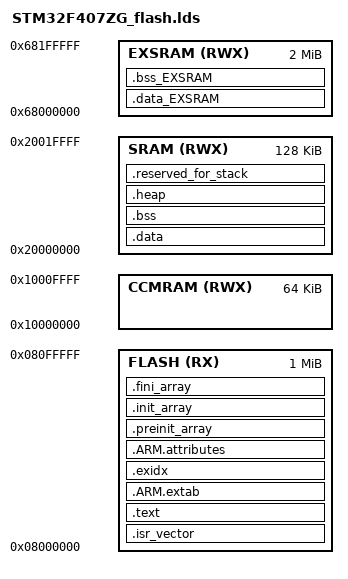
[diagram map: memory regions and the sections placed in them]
/* Generated by LinkerScriptGenerator [http://visualgdb.com/tools/LinkerScriptGenerator]
 * Target: STM32F407ZG
 * The file is provided under the BSD license.
 */

ENTRY(Reset_Handler)

MEMORY
{
	FLASH (RX)   : ORIGIN = 0x08000000, LENGTH = 1M
	SRAM (RWX)   : ORIGIN = 0x20000000, LENGTH = 128K
	CCMRAM (RWX) : ORIGIN = 0x10000000, LENGTH = 64K
  EXSRAM (RWX)   : ORIGIN = 0x68000000, LENGTH = 2M
}

_estack = 0x20020000;

SECTIONS
{
	.isr_vector :
	{
		. = ALIGN(4);
		KEEP(*(.isr_vector))
		. = ALIGN(4);
	} > FLASH

	.text :
	{
		. = ALIGN(4);
		_stext = .;

		*(.text)
		*(.text*)
		*(.rodata)
		*(.rodata*)
		*(.glue_7)
		*(.glue_7t)
		KEEP(*(.init))
		KEEP(*(.fini))
		. = ALIGN(4);
		_etext = .;

	} > FLASH

	.ARM.extab :
	{
		. = ALIGN(4);
		*(.ARM.extab)
		*(.gnu.linkonce.armextab.*)
		. = ALIGN(4);
	} > FLASH

	.exidx :
	{
		. = ALIGN(4);
		PROVIDE(__exidx_start = .);
		*(.ARM.exidx*)
		. = ALIGN(4);
		PROVIDE(__exidx_end = .);
	} > FLASH

	.ARM.attributes :
	{
		*(.ARM.attributes)
	} > FLASH

	.preinit_array :
	{
		PROVIDE(__preinit_array_start = .);
		KEEP(*(.preinit_array*))
		PROVIDE(__preinit_array_end = .);
	} > FLASH

	.init_array :
	{
		PROVIDE(__init_array_start = .);
		KEEP(*(SORT(.init_array.*)))
		KEEP(*(.init_array*))
		PROVIDE(__init_array_end = .);
	} > FLASH

	.fini_array :
	{
		PROVIDE(__fini_array_start = .);
		KEEP(*(.fini_array*))
		KEEP(*(SORT(.fini_array.*)))
		PROVIDE(__fini_array_end = .);
	} > FLASH

	. = ALIGN(4);
	_sidata = .;

	.data : AT(_sidata)
	{
		. = ALIGN(4);
		_sdata = .;

		PROVIDE(__data_start__ = _sdata);
		*(.data)
		*(.data*)
		. = ALIGN(4);

		PROVIDE (__command_start = .);
    		*(.commands);
    		PROVIDE (__command_end = .);
		. = ALIGN(4);

		__ram_persist_start = .;
		*(.ram_persist);
		__ram_persist_end = .;
        . = ALIGN(4);

		_edata = .;

		PROVIDE(__data_end__ = _edata);
	} > SRAM

	.data_EXSRAM : AT (LOADADDR(.data)+SIZEOF(.data))
	{
		. = ALIGN(4);
		_exsdata = .;

		PROVIDE(__exdata_start__ = _exsdata);
		*(.exdata)
		*(.exdata*)
		. = ALIGN(4);
		_exedata = .;

		PROVIDE(__exdata_end__ = _exedata);
	} > EXSRAM 

	.bss_EXSRAM (NOLOAD):
	{
		. = ALIGN(4);
		_exsbss = .;
		PROVIDE(__exbss_start__ = _exsbss);
		*(.exbss)
		*(.exbss*)
		. = ALIGN(4);
		_exebss = .;

		PROVIDE(__exbss_end__ = _exebss);
	} > EXSRAM


	.bss (NOLOAD) :
	{
		. = ALIGN(4);
		_sbss = .;

		PROVIDE(__bss_start__ = _sbss);
		*(.bss)
		*(.bss*)
		*(COMMON)
		. = ALIGN(4);
		_ebss = .;

		PROVIDE(__bss_end__ = _ebss);
	} > SRAM


	PROVIDE(end = .);

	.heap (NOLOAD) :
	{
		. = ALIGN(4);
		PROVIDE(__heap_start__ = .);
		KEEP(*(.heap))
		. = ALIGN(4);
		PROVIDE(__heap_end__ = .);
	} > SRAM

	.reserved_for_stack (NOLOAD) :
	{
		. = ALIGN(4);
		PROVIDE(__reserved_for_stack_start__ = .);
		KEEP(*(.reserved_for_stack))
		. = ALIGN(4);
		PROVIDE(__reserved_for_stack_end__ = .);
	} > SRAM

}

